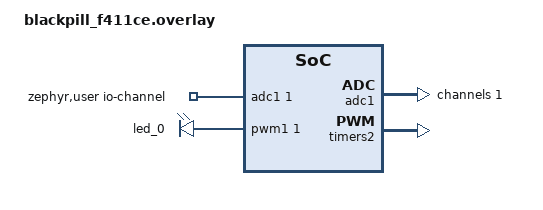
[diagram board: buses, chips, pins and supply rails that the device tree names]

// Define PWM_POLARITY_NORMAL
#include <zephyr/dt-bindings/pwm/pwm.h>

/ {
    aliases {
        my-adc = &adc1;
        my-adc-channel = &adc1_ch1;
        led-0 = &led_0;
    };

	zephyr,user {
		/* adjust channel number according to pinmux in board.dts */
		io-channels = <&adc1 1>;
	};

    // User-defined node for configuring "pwm-leds" subnodes
	// <{LED controller node}, channel, period, flags>
	my-pwm-leds {
		compatible = "pwm-leds";
        status = "okay";

		led_0: pwm_led_0 {
			    pwms = <&pwm1 1 PWM_MSEC(1000) PWM_POLARITY_NORMAL>;
		};
	};
};


// ADC1 (ADC1) channel 1 is connected to A1
&adc1 {
    status = "okay";
    #address-cells = <1>;
    #size-cells = <0>;

    adc1_ch1: channel@1 {
        reg = <1>;
        zephyr,gain = "ADC_GAIN_1";
        zephyr,reference = "ADC_REF_INTERNAL";
        zephyr,vref-mv = <3300>;
        zephyr,acquisition-time = <ADC_ACQ_TIME_DEFAULT>;
        zephyr,resolution = <12>;
    };
};

&timers2 {
    status = "okay";
    pwm1: pwm {
        status = "okay";
        pinctrl-0 = <&tim2_ch1_pa0>;
        pinctrl-names = "default";
    };
};
